# MDR32FG16S1QI register map
Vendor: Milandr; File version: 1.0
CPU: CM3 r1p1, little endian, MPU, no FPU, 3 interrupt priority bits
Registers are 32-bit, read-write, reset 0x0 unless marked. A register's access mark holds for its fields unless they carry their own. Offsets are from the block's base; [hi:lo] are bit positions; {n}, {i} and the like mark numbered series; 'fields as' and 'values as' point back to an identical list.

## MDR_ADC — ADC
Base 0x40088000; register names take the prefix MDR_ADC_
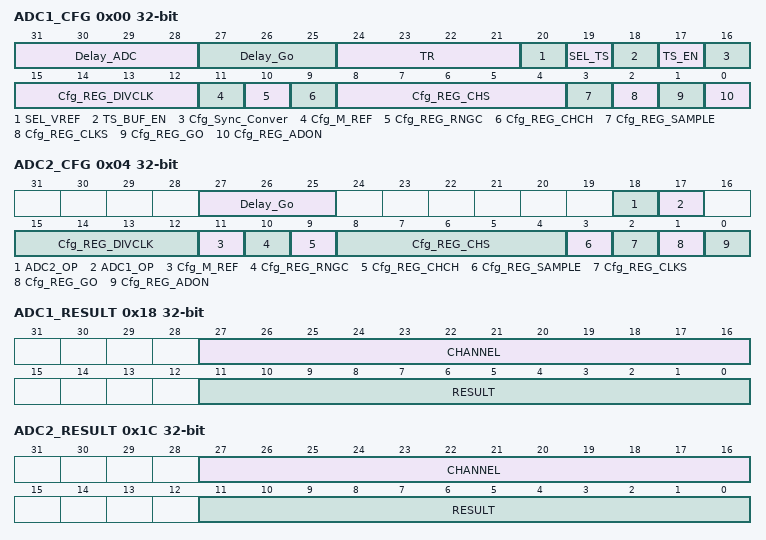
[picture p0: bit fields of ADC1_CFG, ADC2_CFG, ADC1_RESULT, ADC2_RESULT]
0x00 ADC1_CFG — ADC1 Configuration Register
  [31:28] Delay_ADC, [27:25] Delay_Go, [24:21] TR, [20] SEL_VREF, [19] SEL_TS, [18] TS_BUF_EN, [17] TS_EN, [16] Cfg_Sync_Conver, [15:12] Cfg_REG_DIVCLK, [11] Cfg_M_REF, [10] Cfg_REG_RNGC, [9] Cfg_REG_CHCH, [8:4] Cfg_REG_CHS, [3] Cfg_REG_SAMPLE, [2] Cfg_REG_CLKS, [1] Cfg_REG_GO, [0] Cfg_REG_ADON
0x04 ADC2_CFG — ADC2 Configuration Register
  [27:25] Delay_Go, [18] ADC2_OP, [17] ADC1_OP, [15:12] Cfg_REG_DIVCLK, [11] Cfg_M_REF, [10] Cfg_REG_RNGC, [9] Cfg_REG_CHCH, [8:4] Cfg_REG_CHS, [3] Cfg_REG_SAMPLE, [2] Cfg_REG_CLKS, [1] Cfg_REG_GO, [0] Cfg_REG_ADON
0x08 ADC1_H_LEVEL — ADC1 High Level Register
  [11:0] REG_H_LEVEL
0x0C ADC2_H_LEVEL — ADC2 High Level Register
  [11:0] REG_H_LEVEL
0x10 ADC1_L_LEVEL — ADC1 Low Level Register
  [11:0] REG_L_LEVEL
0x14 ADC2_L_LEVEL — ADC2 Low Level Register
  [11:0] REG_L_LEVEL
0x18 ADC1_RESULT
  [27:16] CHANNEL, [11:0] RESULT
0x1C ADC2_RESULT
  [27:16] CHANNEL, [11:0] RESULT
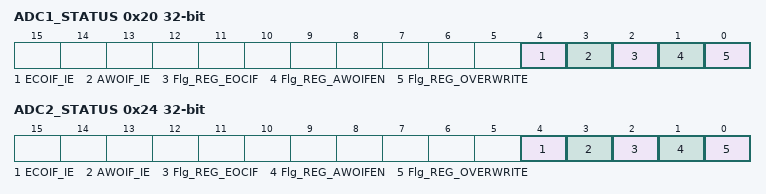
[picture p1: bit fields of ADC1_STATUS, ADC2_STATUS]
0x20 ADC1_STATUS
  [4] ECOIF_IE, [3] AWOIF_IE, [2] Flg_REG_EOCIF, [1] Flg_REG_AWOIFEN, [0] Flg_REG_OVERWRITE
0x24 ADC2_STATUS
  fields as ADC1_STATUS
0x28 ADC1_CHSEL — ADC1 Channel Selector Register
  [31:0] Sl_Ch_Ch_REF
0x2C ADC2_CHSEL — ADC2 Channel Selector Register
  [31:0] Sl_Ch_Ch_REF

## MDR_DAC — DAC
Base 0x40090000; register names take the prefix MDR_DAC_
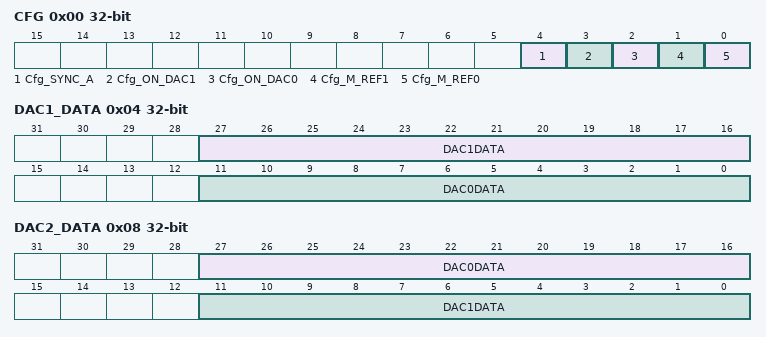
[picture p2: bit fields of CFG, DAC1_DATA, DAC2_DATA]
0x00 CFG — DAC Configuration Register
  [4] Cfg_SYNC_A, [3] Cfg_ON_DAC1, [2] Cfg_ON_DAC0, [1] Cfg_M_REF1, [0] Cfg_M_REF0
0x04 DAC1_DATA
  [27:16] DAC1DATA, [11:0] DAC0DATA
0x08 DAC2_DATA
  [27:16] DAC0DATA, [11:0] DAC1DATA

## MDR_COMP — COMPARATOR
Base 0x40098000; register names take the prefix MDR_COMP_
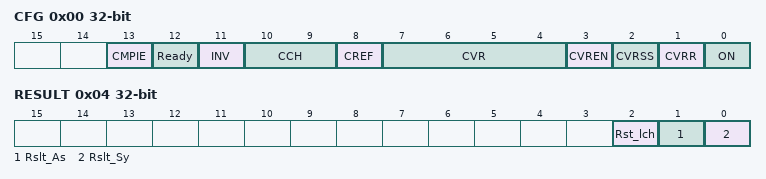
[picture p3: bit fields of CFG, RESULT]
0x00 CFG — COMP Configuration Register
  [13] CMPIE, [12] Ready, [11] INV, [10:9] CCH, [8] CREF, [7:4] CVR, [3] CVREN, [2] CVRSS, [1] CVRR, [0] ON
0x04 RESULT — COMP Result Register
  [2] Rst_lch, [1] Rslt_As, [0] Rslt_Sy
0x08 RESULT_LATCH — COMP Result Latch Register
  [0] Rst_lch

## MDR_PORTA — PORTA
Base 0x400A8000; register names take the prefix MDR_PORTA_
Same registers: MDR_PORTB 0x400B0000 (register names take the prefix MDR_PORTB_), MDR_PORTC 0x400B8000 (register names take the prefix MDR_PORTC_), MDR_PORTD 0x400C0000 (register names take the prefix MDR_PORTD_), MDR_PORTE 0x400C8000 (register names take the prefix MDR_PORTE_), MDR_PORTF 0x400E8000 (register names take the prefix MDR_PORTF_)
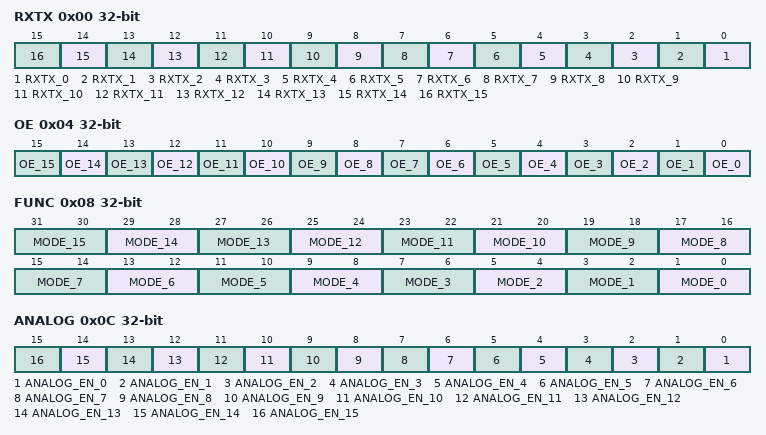
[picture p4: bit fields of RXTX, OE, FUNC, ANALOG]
0x00 RXTX — PORT Data Register
  [n] RXTX_{n} (n=0..15)
0x04 OE — PORT Output Enable Register
  [n] OE_{n} (n=0..15)
0x08 FUNC — PORT Function Register
  [2n+1:2n] MODE_{n} (n=0..15)
0x0C ANALOG — PORT Analog Function Register
  [n] ANALOG_EN_{n} (n=0..15)
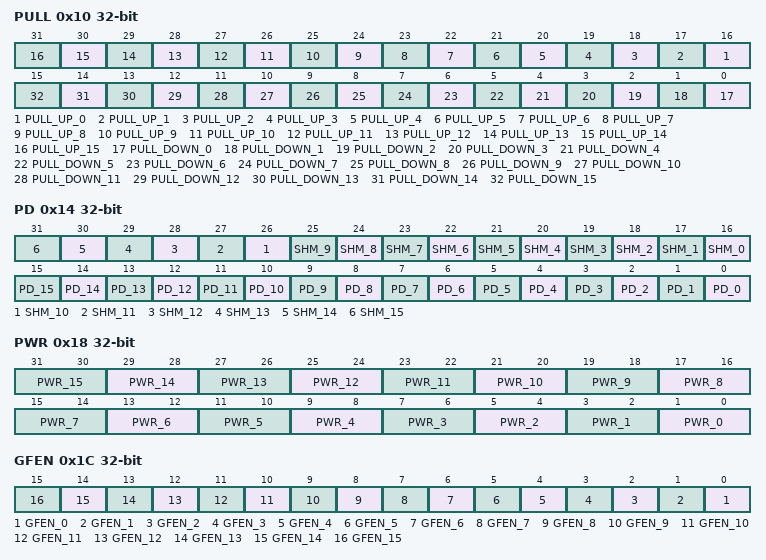
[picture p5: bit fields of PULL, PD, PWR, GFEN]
0x10 PULL — PORT Pull Up/Down Register
  [n+16] PULL_UP_{n} (n=0..15), [n] PULL_DOWN_{n} (n=0..15)
0x14 PD — PORT Driver Mode Register
  [n+16] SHM_{n} (n=0..15), [n] PD_{n} (n=0..15)
0x18 PWR — PORT Power Register
  [2n+1:2n] PWR_{n} (n=0..15)
0x1C GFEN — PORT Filter Configuration Register
  [n] GFEN_{n} (n=0..15)
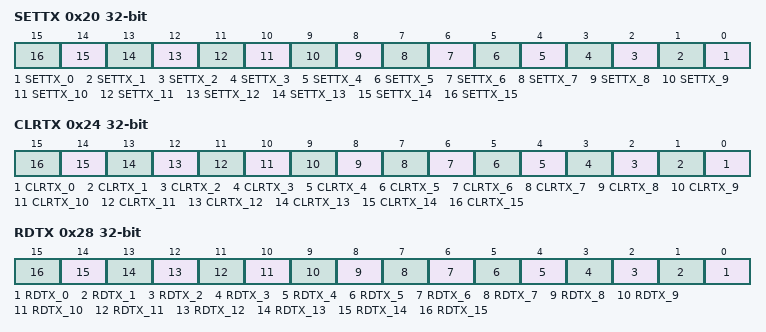
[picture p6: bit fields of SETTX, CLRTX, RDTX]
0x20 SETTX — Set Pin in function PORT
  [n] SETTX_{n} (n=0..15)
0x24 CLRTX — Clear Pin in function PORT
  [n] CLRTX_{n} (n=0..15)
0x28 RDTX ro — Read Pin out in function PORT
  [n] RDTX_{n} rw (n=0..15)

## MDR_BKP — BACKUP
Base 0x400D8000; register names take the prefix MDR_BKP_
{0x0+4i} REG_{i:02} (i=0..9) — Backup Register {i}
  [31:0] BKP_REG
0x28 REG_0A — Backup Register 10
  [31:0] BKP_REG
0x2C REG_0B — Backup Register 11
  [31:0] BKP_REG
0x30 REG_0C — Backup Register 12
  [31:0] BKP_REG
0x34 REG_0D — Backup Register 13
  [31:0] BKP_REG
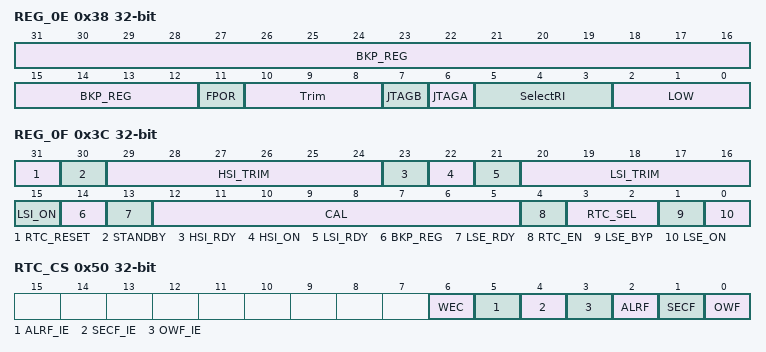
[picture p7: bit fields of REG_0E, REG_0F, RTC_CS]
0x38 REG_0E — Backup Register 14
  [31:12] BKP_REG, [11] FPOR, [10:8] Trim, [7] JTAGB, [6] JTAGA, [5:3] SelectRI, [2:0] LOW
0x3C REG_0F — Backup Register 15
  [31] RTC_RESET, [30] STANDBY, [29:24] HSI_TRIM, [23] HSI_RDY, [22] HSI_ON, [21] LSI_RDY, [20:16] LSI_TRIM, [15] LSI_ON, [14] BKP_REG, [13] LSE_RDY, [12:5] CAL, [4] RTC_EN, [3:2] RTC_SEL, [1] LSE_BYP, [0] LSE_ON
0x40 RTC_CNT — Realtime Clock Counter Register
0x44 RTC_DIV — Realtime Prescaler Counter Register
  [19:0] RTC_DIV
0x48 RTC_PRL — Realtime Prescaler Auto-Reload Value Register
  [19:0] RTC_PRL
0x4C RTC_ALRM — Realtime Alarm Register
0x50 RTC_CS — Backup Realtime clock Register
  [6] WEC, [5] ALRF_IE, [4] SECF_IE, [3] OWF_IE, [2] ALRF, [1] SECF, [0] OWF

## MDR_EBC — EBC
Base 0x400F0000; register names take the prefix MDR_EBC_
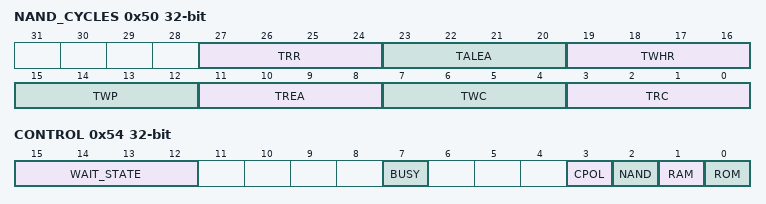
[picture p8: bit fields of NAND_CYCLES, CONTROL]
0x50 NAND_CYCLES — EBC NAND Timing Register
  [27:24] TRR, [23:20] TALEA, [19:16] TWHR, [15:12] TWP, [11:8] TREA, [7:4] TWC, [3:0] TRC
0x54 CONTROL — EBC Control Register
  [15:12] WAIT_STATE, [7] BUSY, [3] CPOL, [2] NAND, [1] RAM, [0] ROM

## MDR_CRPT — CRPT
Base 0x30000080; register names take the prefix MDR_CRPT_
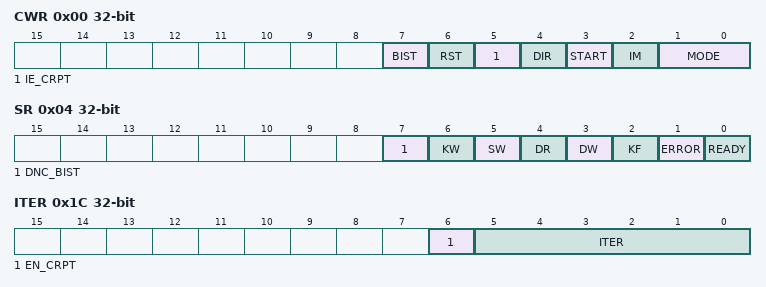
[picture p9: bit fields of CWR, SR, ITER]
0x00 CWR — CWR Configuration Register
  [7] BIST, [6] RST, [5] IE_CRPT, [4] DIR, [3] START, [2] IM, [1:0] MODE
0x04 SR ro — SR Status Register
  [7] DNC_BIST, [6] KW, [5] SW, [4] DR, [3] DW, [2] KF, [1] ERROR, [0] READY
0x08 DATA
  [15:0] DATA
0x0C KR — Key Register
  [15:0] KEY
0x10 CR — Const Register
  [15:0] CONST
0x14 SYNR — Sync Parcel Register
  [15:0] SYNR
0x18 IMIT — Imitation Register
  [15:0] IMIT
0x1C ITER — Number of iteration Register
  [6] EN_CRPT, [5:0] ITER

## MDR_BSP1 — BSP1
Base 0x30000040; register names take the prefix MDR_BSP1_
Same registers: MDR_BSP2 0x30000050 (register names take the prefix MDR_BSP2_), MDR_BSP3 0x30000060 (register names take the prefix MDR_BSP3_)
0x00 DDR
  [31:0] DATA
0x04 DXR
  [31:0] DATA
0x08 SPSA
  [3:0] DATA
0x0C SPCR
  [31:0] DATA
